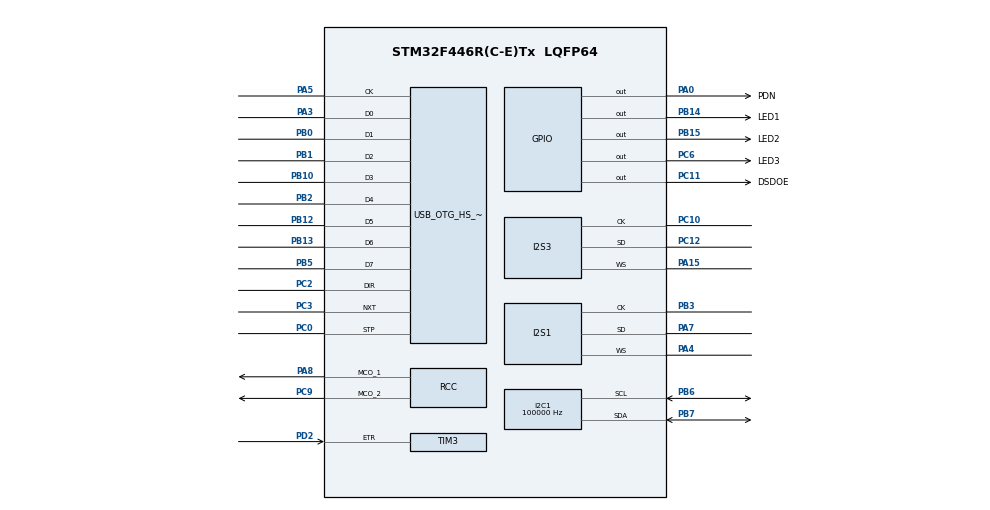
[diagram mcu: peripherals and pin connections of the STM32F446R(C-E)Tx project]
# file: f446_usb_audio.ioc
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Dma.MEMTOMEM.2.Direction=DMA_MEMORY_TO_MEMORY
Dma.MEMTOMEM.2.FIFOMode=DMA_FIFOMODE_ENABLE
Dma.MEMTOMEM.2.FIFOThreshold=DMA_FIFO_THRESHOLD_FULL
Dma.MEMTOMEM.2.Instance=DMA2_Stream0
Dma.MEMTOMEM.2.MemBurst=DMA_MBURST_SINGLE
Dma.MEMTOMEM.2.MemDataAlignment=DMA_MDATAALIGN_WORD
Dma.MEMTOMEM.2.MemInc=DMA_MINC_ENABLE
Dma.MEMTOMEM.2.Mode=DMA_NORMAL
Dma.MEMTOMEM.2.PeriphBurst=DMA_PBURST_SINGLE
Dma.MEMTOMEM.2.PeriphDataAlignment=DMA_PDATAALIGN_WORD
Dma.MEMTOMEM.2.PeriphInc=DMA_PINC_ENABLE
Dma.MEMTOMEM.2.Priority=DMA_PRIORITY_LOW
Dma.MEMTOMEM.3.Direction=DMA_MEMORY_TO_MEMORY
Dma.MEMTOMEM.3.FIFOMode=DMA_FIFOMODE_ENABLE
Dma.MEMTOMEM.3.FIFOThreshold=DMA_FIFO_THRESHOLD_FULL
Dma.MEMTOMEM.3.Instance=DMA2_Stream1
Dma.MEMTOMEM.3.MemBurst=DMA_MBURST_SINGLE
Dma.MEMTOMEM.3.MemDataAlignment=DMA_MDATAALIGN_WORD
Dma.MEMTOMEM.3.MemInc=DMA_MINC_ENABLE
Dma.MEMTOMEM.3.Mode=DMA_NORMAL
Dma.MEMTOMEM.3.PeriphBurst=DMA_PBURST_SINGLE
Dma.MEMTOMEM.3.PeriphDataAlignment=DMA_PDATAALIGN_WORD
Dma.MEMTOMEM.3.PeriphInc=DMA_PINC_DISABLE
Dma.MEMTOMEM.3.Priority=DMA_PRIORITY_LOW
Dma.Request0=SPI3_TX
Dma.Request1=SPI1_TX
Dma.Request2=MEMTOMEM
Dma.Request3=MEMTOMEM
Dma.SPI1_TX.1.Direction=DMA_MEMORY_TO_PERIPH
Dma.SPI1_TX.1.FIFOMode=DMA_FIFOMODE_ENABLE
Dma.SPI1_TX.1.FIFOThreshold=DMA_FIFO_THRESHOLD_FULL
Dma.SPI1_TX.1.Instance=DMA2_Stream3
Dma.SPI1_TX.1.MemBurst=DMA_MBURST_INC4
Dma.SPI1_TX.1.MemDataAlignment=DMA_MDATAALIGN_WORD
Dma.SPI1_TX.1.MemInc=DMA_MINC_ENABLE
Dma.SPI1_TX.1.Mode=DMA_CIRCULAR
Dma.SPI1_TX.1.PeriphBurst=DMA_PBURST_SINGLE
Dma.SPI1_TX.1.PeriphDataAlignment=DMA_PDATAALIGN_HALFWORD
Dma.SPI1_TX.1.PeriphInc=DMA_PINC_DISABLE
Dma.SPI1_TX.1.Priority=DMA_PRIORITY_LOW
Dma.SPI3_TX.0.Direction=DMA_MEMORY_TO_PERIPH
Dma.SPI3_TX.0.FIFOMode=DMA_FIFOMODE_ENABLE
Dma.SPI3_TX.0.FIFOThreshold=DMA_FIFO_THRESHOLD_FULL
Dma.SPI3_TX.0.Instance=DMA1_Stream5
Dma.SPI3_TX.0.MemBurst=DMA_MBURST_INC4
Dma.SPI3_TX.0.MemDataAlignment=DMA_MDATAALIGN_WORD
Dma.SPI3_TX.0.MemInc=DMA_MINC_ENABLE
Dma.SPI3_TX.0.Mode=DMA_CIRCULAR
Dma.SPI3_TX.0.PeriphBurst=DMA_PBURST_SINGLE
Dma.SPI3_TX.0.PeriphDataAlignment=DMA_PDATAALIGN_HALFWORD
Dma.SPI3_TX.0.PeriphInc=DMA_PINC_DISABLE
Dma.SPI3_TX.0.Priority=DMA_PRIORITY_LOW
I2C1.ClockSpeed=100000
I2C1.I2C_Mode=I2C_Standard
I2S1.AudioFreq=I2S_AUDIOFREQ_48K
I2S1.DataFormat=I2S_DATAFORMAT_32B
I2S1.ErrorAudioFreq=0.0 %
I2S1.FullDuplexMode=I2S_FULLDUPLEXMODE_DISABLE
I2S1.Instance=SPI$Index
I2S1.RealAudioFreq=48.0 KHz
I2S1.VirtualMode=I2S_MODE_SLAVE
I2S3.AudioFreq=I2S_AUDIOFREQ_48K
I2S3.CPOL=I2S_CPOL_LOW
I2S3.DataFormat=I2S_DATAFORMAT_32B
I2S3.ErrorAudioFreq=0.0 %
I2S3.FullDuplexMode=I2S_FULLDUPLEXMODE_DISABLE
I2S3.Instance=SPI$Index
I2S3.RealAudioFreq=48.0 KHz
I2S3.Standard=I2S_STANDARD_PHILIPS
I2S3.VirtualMode=I2S_MODE_MASTER
Mcu.Family=STM32F4
Mcu.Name=STM32F446R(C-E)Tx
Mcu.Package=LQFP64
NVIC.DMA1_Stream5_IRQn=true\:0\:0\:true\:false\:true\:false\:true\:true
NVIC.DMA2_Stream0_IRQn=true\:0\:0\:true\:false\:true\:true\:true\:true
NVIC.DMA2_Stream3_IRQn=true\:0\:0\:true\:false\:true\:false\:true\:true
NVIC.I2C1_EV_IRQn=true\:0\:0\:true\:false\:true\:true\:true\:true
NVIC.OTG_HS_IRQn=true\:0\:0\:true\:false\:true\:true\:true\:true
NVIC.PriorityGroup=NVIC_PRIORITYGROUP_4
NVIC.TIM3_IRQn=true\:0\:0\:true\:false\:true\:true\:true\:true
PA0-WKUP.GPIO_Label=PDN
PA0-WKUP.GPIO_Speed=GPIO_SPEED_FREQ_LOW
PA0-WKUP.PinState=GPIO_PIN_SET
PA0-WKUP.Signal=GPIO_Output
PA13.Mode=Serial_Wire
PA13.Signal=SYS_JTMS-SWDIO
PA14.Mode=Serial_Wire
PA14.Signal=SYS_JTCK-SWCLK
PA15.GPIO_PuPd=GPIO_PULLDOWN
PA15.GPIO_Speed=GPIO_SPEED_FREQ_VERY_HIGH
PA15.Mode=Half_Duplex_Master
PA15.Signal=I2S3_WS
PA3.Mode=Device_HS
PA3.Signal=USB_OTG_HS_ULPI_D0
PA4.GPIO_PuPd=GPIO_PULLDOWN
PA4.GPIO_Speed=GPIO_SPEED_FREQ_VERY_HIGH
PA4.Mode=Half_Duplex_Slave
PA4.Signal=I2S1_WS
PA5.Mode=Device_HS
PA5.Signal=USB_OTG_HS_ULPI_CK
PA7.GPIO_PuPd=GPIO_PULLDOWN
PA7.GPIO_Speed=GPIO_SPEED_FREQ_VERY_HIGH
PA7.Mode=Half_Duplex_Slave
PA7.Signal=I2S1_SD
PA8.GPIO_Speed=GPIO_SPEED_FREQ_VERY_HIGH
PA8.Mode=Clock-out-1
PA8.Signal=RCC_MCO_1
PB0.Mode=Device_HS
PB0.Signal=USB_OTG_HS_ULPI_D1
PB1.Mode=Device_HS
PB1.Signal=USB_OTG_HS_ULPI_D2
PB10.Mode=Device_HS
PB10.Signal=USB_OTG_HS_ULPI_D3
PB12.Mode=Device_HS
PB12.Signal=USB_OTG_HS_ULPI_D5
PB13.Mode=Device_HS
PB13.Signal=USB_OTG_HS_ULPI_D6
PB14.GPIO_Label=LED1
PB14.PinState=GPIO_PIN_SET
PB14.Signal=GPIO_Output
PB15.GPIO_Label=LED2
PB15.PinState=GPIO_PIN_SET
PB15.Signal=GPIO_Output
PB2.Mode=Device_HS
PB2.Signal=USB_OTG_HS_ULPI_D4
PB3.GPIO_PuPd=GPIO_PULLDOWN
PB3.GPIO_Speed=GPIO_SPEED_FREQ_VERY_HIGH
PB3.Mode=Half_Duplex_Slave
PB3.Signal=I2S1_CK
PB5.Mode=Device_HS
PB5.Signal=USB_OTG_HS_ULPI_D7
PB6.Mode=I2C
PB6.Signal=I2C1_SCL
PB7.Mode=I2C
PB7.Signal=I2C1_SDA
PC0.Mode=Device_HS
PC0.Signal=USB_OTG_HS_ULPI_STP
PC10.GPIO_PuPd=GPIO_PULLDOWN
PC10.GPIO_Speed=GPIO_SPEED_FREQ_VERY_HIGH
PC10.Mode=Half_Duplex_Master
PC10.Signal=I2S3_CK
PC11.GPIO_Label=DSDOE
PC11.GPIO_PuPd=GPIO_NOPULL
PC11.PinState=GPIO_PIN_RESET
PC11.Signal=GPIO_Output
PC12.GPIO_PuPd=GPIO_PULLDOWN
PC12.GPIO_Speed=GPIO_SPEED_FREQ_VERY_HIGH
PC12.Mode=Half_Duplex_Master
PC12.Signal=I2S3_SD
PC2.Mode=Device_HS
PC2.Signal=USB_OTG_HS_ULPI_DIR
PC3.Mode=Device_HS
PC3.Signal=USB_OTG_HS_ULPI_NXT
PC6.GPIO_Label=LED3
PC6.PinState=GPIO_PIN_SET
PC6.Signal=GPIO_Output
PC9.GPIO_Speed=GPIO_SPEED_FREQ_VERY_HIGH
PC9.Mode=Clock-out-2
PC9.Signal=RCC_MCO_2
PD2.Signal=S_TIM3_ETR
PH0-OSC_IN.Mode=HSE-External-Clock-Source
PH0-OSC_IN.Signal=RCC_OSC_IN
PH1-OSC_OUT.Mode=HSE-External-Clock-Source
PH1-OSC_OUT.Signal=RCC_OSC_OUT
ProjectManager.HeapSize=0x400
ProjectManager.StackSize=0x800
ProjectManager.TargetToolchain=STM32CubeIDE
RCC.AHBFreq_Value=192000000
RCC.APB1CLKDivider=RCC_HCLK_DIV4
RCC.APB1Freq_Value=48000000
RCC.APB1TimFreq_Value=96000000
RCC.APB2CLKDivider=RCC_HCLK_DIV2
RCC.APB2Freq_Value=96000000
RCC.APB2TimFreq_Value=192000000
RCC.CortexFreq_Value=192000000
RCC.EXTERNAL_CLOCK_VALUE=49152000
RCC.HCLKFreq_Value=192000000
RCC.HSE_Timout=100
RCC.HSE_VALUE=24576000
RCC.PLLI2SN=128
RCC.PLLN=250
RCC.PLLP=RCC_PLLP_DIV4
RCC.PLLSAIM=24
RCC.PLLSourceVirtual=RCC_PLLSOURCE_HSE
RCC.PWREXT_OverDrive=PWREXT_OverDrive_ACTIVATED
RCC.PWR_Regulator_Voltage_Scale=PWR_REGULATOR_VOLTAGE_SCALE1
RCC.RCC_MCO1Source=RCC_MCO1SOURCE_PLLCLK
RCC.RCC_MCO2Source=RCC_MCO2SOURCE_PLLI2SCLK
RCC.RCC_MCODiv1=RCC_MCODIV_4
RCC.RCC_MCODiv2=RCC_MCODIV_4
RCC.SYSCLKFreq_VALUE=192000000
RCC.SYSCLKSource=RCC_SYSCLKSOURCE_PLLRCLK
RCC.USBFreq_Value=192000000
RCC.VCOOutputFreq_Value=384000000
SH.S_TIM3_ETR.0=TIM3_ETR,TriggerSource_ETR
TIM3.Period=511
USB_OTG_HS.Sof_enable-Device_HS=DISABLE
USB_OTG_HS.VirtualMode-Device_HS=Device_HS
USB_OTG_HS.dma_enable-Device_HS=ENABLE
USB_OTG_HS.lpm_enable-Device_HS=DISABLE
USB_OTG_HS.use_dedicated_ep1-Device_HS=DISABLE
VP_TIM3_VS_ControllerModeClock.Mode=Clock Mode
board=custom

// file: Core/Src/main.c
/* USER CODE BEGIN Header */
/**
  ******************************************************************************
  * @file           : main.c
  * @brief          : Main program body
  ******************************************************************************
  * @attention
  *
  * Copyright (c) 2023 STMicroelectronics.
  * All rights reserved.
  *
  * This software is licensed under terms that can be found in the LICENSE file
  * in the root directory of this software component.
  * If no LICENSE file comes with this software, it is provided AS-IS.
  *
  ******************************************************************************
  */
/* USER CODE END Header */
#include "main.h"

/* USER CODE BEGIN Includes */
#include "usb_device.h"
#include "ak4490r.h"
/* USER CODE END Includes */

 I2C_HandleTypeDef hi2c1;

I2S_HandleTypeDef hi2s1;
I2S_HandleTypeDef hi2s3;
DMA_HandleTypeDef hdma_spi1_tx;
DMA_HandleTypeDef hdma_spi3_tx;

PCD_HandleTypeDef hpcd_USB_OTG_HS;

DMA_HandleTypeDef hdma_memtomem_dma2_stream0;
DMA_HandleTypeDef hdma_memtomem_dma2_stream1;

void SystemClock_Config(void);
void PeriphCommonClock_Config(void);
static void MX_GPIO_Init(void);
static void MX_DMA_Init(void);
static void MX_I2C1_Init(void);
static void MX_I2S1_Init(void);
static void MX_I2S3_Init(void);
static void MX_TIM3_Init(void);
static void MX_USB_OTG_HS_PCD_Init(void);

int main(void)
{

  /* MCU Configuration--------------------------------------------------------*/

  /* Reset of all peripherals, Initializes the Flash interface and the Systick. */
  HAL_Init();

  /* Configure the system clock */
  SystemClock_Config();

/* Configure the peripherals common clocks */
  PeriphCommonClock_Config();

  /* Initialize all configured peripherals */
  MX_GPIO_Init();
  MX_DMA_Init();
  MX_I2C1_Init();
  MX_I2S1_Init();
  MX_I2S3_Init();
  MX_TIM3_Init();
  MX_USB_OTG_HS_PCD_Init();
  /* USER CODE BEGIN 2 */
  MX_USB_DEVICE_Init();

  // For LRCK counting for feedback
  LL_TIM_EnableIT_UPDATE(TIM3);
  LL_TIM_EnableCounter(TIM3);
  /* USER CODE END 2 */

  /* Infinite loop */
  /* USER CODE BEGIN WHILE */
  while (1)
  {
  	AK4490R_ProcessEvents();
    /* USER CODE END WHILE */

  }
}

void SystemClock_Config(void)
{
  LL_FLASH_SetLatency(LL_FLASH_LATENCY_5);
  while(LL_FLASH_GetLatency()!= LL_FLASH_LATENCY_5)
  {
  }
  LL_PWR_SetRegulVoltageScaling(LL_PWR_REGU_VOLTAGE_SCALE1);
  LL_PWR_EnableOverDriveMode();
  LL_RCC_HSE_EnableBypass();
  LL_RCC_HSE_Enable();

   /* Wait till HSE is ready */
  while(LL_RCC_HSE_IsReady() != 1)
  {

  }
  LL_RCC_PLL_ConfigDomain_SYS(LL_RCC_PLLSOURCE_HSE, LL_RCC_PLLM_DIV_16, 250, LL_RCC_PLLP_DIV_4);
  LL_RCC_PLL_ConfigDomain_SYS(LL_RCC_PLLSOURCE_HSE, LL_RCC_PLLM_DIV_16, 250, LL_RCC_PLLR_DIV_2);
  RCC->PLLCFGR |= 1 << 16;
  LL_RCC_PLL_Enable();

   /* Wait till PLL is ready */
  while(LL_RCC_PLL_IsReady() != 1)
  {

  }
  LL_RCC_SetAHBPrescaler(LL_RCC_SYSCLK_DIV_1);
  LL_RCC_SetAPB1Prescaler(LL_RCC_APB1_DIV_4);
  LL_RCC_SetAPB2Prescaler(LL_RCC_APB2_DIV_2);
  LL_RCC_SetSysClkSource(LL_RCC_SYS_CLKSOURCE_PLLR);

   /* Wait till System clock is ready */
  while(LL_RCC_GetSysClkSource() != LL_RCC_SYS_CLKSOURCE_STATUS_PLLR)
  {

  }
  LL_SetSystemCoreClock(192000000);

   /* Update the time base */
  if (HAL_InitTick (TICK_INT_PRIORITY) != HAL_OK)
  {
    Error_Handler();
  }
  LL_RCC_ConfigMCO(LL_RCC_MCO1SOURCE_PLLCLK, LL_RCC_MCO1_DIV_4);
  LL_RCC_ConfigMCO(LL_RCC_MCO2SOURCE_PLLI2S, LL_RCC_MCO2_DIV_4);
  LL_RCC_SetTIMPrescaler(LL_RCC_TIM_PRESCALER_TWICE);
}

void PeriphCommonClock_Config(void)
{
  LL_RCC_PLLI2S_ConfigDomain_I2S(LL_RCC_PLLSOURCE_HSE, LL_RCC_PLLI2SM_DIV_16, 128, LL_RCC_PLLI2SR_DIV_2);
  LL_RCC_PLLI2S_Enable();

   /* Wait till PLL is ready */
  while(LL_RCC_PLLI2S_IsReady() != 1)
  {

  }
}

static void MX_I2C1_Init(void)
{

  hi2c1.Instance = I2C1;
  hi2c1.Init.ClockSpeed = 100000;
  hi2c1.Init.DutyCycle = I2C_DUTYCYCLE_2;
  hi2c1.Init.OwnAddress1 = 0;
  hi2c1.Init.AddressingMode = I2C_ADDRESSINGMODE_7BIT;
  hi2c1.Init.DualAddressMode = I2C_DUALADDRESS_DISABLE;
  hi2c1.Init.OwnAddress2 = 0;
  hi2c1.Init.GeneralCallMode = I2C_GENERALCALL_DISABLE;
  hi2c1.Init.NoStretchMode = I2C_NOSTRETCH_DISABLE;
  if (HAL_I2C_Init(&hi2c1) != HAL_OK)
  {
    Error_Handler();
  }

}

static void MX_I2S1_Init(void)
{

  hi2s1.Instance = SPI1;
  hi2s1.Init.Mode = I2S_MODE_SLAVE_TX;
  hi2s1.Init.Standard = I2S_STANDARD_PHILIPS;
  hi2s1.Init.DataFormat = I2S_DATAFORMAT_32B;
  hi2s1.Init.MCLKOutput = I2S_MCLKOUTPUT_DISABLE;
  hi2s1.Init.AudioFreq = I2S_AUDIOFREQ_48K;
  hi2s1.Init.CPOL = I2S_CPOL_LOW;
  hi2s1.Init.ClockSource = I2S_CLOCK_PLL;
  hi2s1.Init.FullDuplexMode = I2S_FULLDUPLEXMODE_DISABLE;
  if (HAL_I2S_Init(&hi2s1) != HAL_OK)
  {
    Error_Handler();
  }

}

static void MX_I2S3_Init(void)
{

  hi2s3.Instance = SPI3;
  hi2s3.Init.Mode = I2S_MODE_MASTER_TX;
  hi2s3.Init.Standard = I2S_STANDARD_PHILIPS;
  hi2s3.Init.DataFormat = I2S_DATAFORMAT_32B;
  hi2s3.Init.MCLKOutput = I2S_MCLKOUTPUT_DISABLE;
  hi2s3.Init.AudioFreq = I2S_AUDIOFREQ_48K;
  hi2s3.Init.CPOL = I2S_CPOL_LOW;
  hi2s3.Init.ClockSource = I2S_CLOCK_PLL;
  hi2s3.Init.FullDuplexMode = I2S_FULLDUPLEXMODE_DISABLE;
  if (HAL_I2S_Init(&hi2s3) != HAL_OK)
  {
    Error_Handler();
  }

}

static void MX_TIM3_Init(void)
{

  LL_TIM_InitTypeDef TIM_InitStruct = {0};

  LL_GPIO_InitTypeDef GPIO_InitStruct = {0};

  /* Peripheral clock enable */
  LL_APB1_GRP1_EnableClock(LL_APB1_GRP1_PERIPH_TIM3);

  LL_AHB1_GRP1_EnableClock(LL_AHB1_GRP1_PERIPH_GPIOD);
  /**TIM3 GPIO Configuration
  PD2   ------> TIM3_ETR
  */
  GPIO_InitStruct.Pin = LL_GPIO_PIN_2;
  GPIO_InitStruct.Mode = LL_GPIO_MODE_ALTERNATE;
  GPIO_InitStruct.Speed = LL_GPIO_SPEED_FREQ_LOW;
  GPIO_InitStruct.OutputType = LL_GPIO_OUTPUT_PUSHPULL;
  GPIO_InitStruct.Pull = LL_GPIO_PULL_NO;
  GPIO_InitStruct.Alternate = LL_GPIO_AF_2;
  LL_GPIO_Init(GPIOD, &GPIO_InitStruct);

  /* TIM3 interrupt Init */
  NVIC_SetPriority(TIM3_IRQn, NVIC_EncodePriority(NVIC_GetPriorityGrouping(),0, 0));
  NVIC_EnableIRQ(TIM3_IRQn);

  TIM_InitStruct.Prescaler = 0;
  TIM_InitStruct.CounterMode = LL_TIM_COUNTERMODE_UP;
  TIM_InitStruct.Autoreload = 511;
  TIM_InitStruct.ClockDivision = LL_TIM_CLOCKDIVISION_DIV1;
  LL_TIM_Init(TIM3, &TIM_InitStruct);
  LL_TIM_DisableARRPreload(TIM3);
  LL_TIM_SetTriggerInput(TIM3, LL_TIM_TS_ETRF);
  LL_TIM_SetClockSource(TIM3, LL_TIM_CLOCKSOURCE_EXT_MODE1);
  LL_TIM_DisableExternalClock(TIM3);
  LL_TIM_ConfigETR(TIM3, LL_TIM_ETR_POLARITY_NONINVERTED, LL_TIM_ETR_PRESCALER_DIV1, LL_TIM_ETR_FILTER_FDIV1);
  LL_TIM_DisableIT_TRIG(TIM3);
  LL_TIM_DisableDMAReq_TRIG(TIM3);
  LL_TIM_SetTriggerOutput(TIM3, LL_TIM_TRGO_RESET);
  LL_TIM_DisableMasterSlaveMode(TIM3);

}

static void MX_USB_OTG_HS_PCD_Init(void)
{

  hpcd_USB_OTG_HS.Instance = USB_OTG_HS;
  hpcd_USB_OTG_HS.Init.dev_endpoints = 8;
  hpcd_USB_OTG_HS.Init.speed = PCD_SPEED_HIGH;
  hpcd_USB_OTG_HS.Init.dma_enable = ENABLE;
  hpcd_USB_OTG_HS.Init.phy_itface = USB_OTG_ULPI_PHY;
  hpcd_USB_OTG_HS.Init.Sof_enable = DISABLE;
  hpcd_USB_OTG_HS.Init.low_power_enable = DISABLE;
  hpcd_USB_OTG_HS.Init.lpm_enable = DISABLE;
  hpcd_USB_OTG_HS.Init.vbus_sensing_enable = DISABLE;
  hpcd_USB_OTG_HS.Init.use_dedicated_ep1 = DISABLE;
  hpcd_USB_OTG_HS.Init.use_external_vbus = DISABLE;
  if (HAL_PCD_Init(&hpcd_USB_OTG_HS) != HAL_OK)
  {
    Error_Handler();
  }
  /* USER CODE BEGIN USB_OTG_HS_Init 2 */
  HAL_PCDEx_SetRxFiFo(&hpcd_USB_OTG_HS, 0x200);
  HAL_PCDEx_SetTxFiFo(&hpcd_USB_OTG_HS, 0, 0x80);
  HAL_PCDEx_SetTxFiFo(&hpcd_USB_OTG_HS, 1, 0x174);
  /* USER CODE END USB_OTG_HS_Init 2 */

}

static void MX_DMA_Init(void)
{

  /* DMA controller clock enable */
  __HAL_RCC_DMA1_CLK_ENABLE();
  __HAL_RCC_DMA2_CLK_ENABLE();

  /* Configure DMA request hdma_memtomem_dma2_stream0 on DMA2_Stream0 */
  hdma_memtomem_dma2_stream0.Instance = DMA2_Stream0;
  hdma_memtomem_dma2_stream0.Init.Channel = DMA_CHANNEL_0;
  hdma_memtomem_dma2_stream0.Init.Direction = DMA_MEMORY_TO_MEMORY;
  hdma_memtomem_dma2_stream0.Init.PeriphInc = DMA_PINC_ENABLE;
  hdma_memtomem_dma2_stream0.Init.MemInc = DMA_MINC_ENABLE;
  hdma_memtomem_dma2_stream0.Init.PeriphDataAlignment = DMA_PDATAALIGN_WORD;
  hdma_memtomem_dma2_stream0.Init.MemDataAlignment = DMA_MDATAALIGN_WORD;
  hdma_memtomem_dma2_stream0.Init.Mode = DMA_NORMAL;
  hdma_memtomem_dma2_stream0.Init.Priority = DMA_PRIORITY_LOW;
  hdma_memtomem_dma2_stream0.Init.FIFOMode = DMA_FIFOMODE_ENABLE;
  hdma_memtomem_dma2_stream0.Init.FIFOThreshold = DMA_FIFO_THRESHOLD_FULL;
  hdma_memtomem_dma2_stream0.Init.MemBurst = DMA_MBURST_SINGLE;
  hdma_memtomem_dma2_stream0.Init.PeriphBurst = DMA_PBURST_SINGLE;
  if (HAL_DMA_Init(&hdma_memtomem_dma2_stream0) != HAL_OK)
  {
    Error_Handler( );
  }

  /* Configure DMA request hdma_memtomem_dma2_stream1 on DMA2_Stream1 */
  hdma_memtomem_dma2_stream1.Instance = DMA2_Stream1;
  hdma_memtomem_dma2_stream1.Init.Channel = DMA_CHANNEL_0;
  hdma_memtomem_dma2_stream1.Init.Direction = DMA_MEMORY_TO_MEMORY;
  hdma_memtomem_dma2_stream1.Init.PeriphInc = DMA_PINC_DISABLE;
  hdma_memtomem_dma2_stream1.Init.MemInc = DMA_MINC_ENABLE;
  hdma_memtomem_dma2_stream1.Init.PeriphDataAlignment = DMA_PDATAALIGN_WORD;
  hdma_memtomem_dma2_stream1.Init.MemDataAlignment = DMA_MDATAALIGN_WORD;
  hdma_memtomem_dma2_stream1.Init.Mode = DMA_NORMAL;
  hdma_memtomem_dma2_stream1.Init.Priority = DMA_PRIORITY_LOW;
  hdma_memtomem_dma2_stream1.Init.FIFOMode = DMA_FIFOMODE_ENABLE;
  hdma_memtomem_dma2_stream1.Init.FIFOThreshold = DMA_FIFO_THRESHOLD_FULL;
  hdma_memtomem_dma2_stream1.Init.MemBurst = DMA_MBURST_SINGLE;
  hdma_memtomem_dma2_stream1.Init.PeriphBurst = DMA_PBURST_SINGLE;
  if (HAL_DMA_Init(&hdma_memtomem_dma2_stream1) != HAL_OK)
  {
    Error_Handler( );
  }

  /* DMA interrupt init */
  /* DMA1_Stream5_IRQn interrupt configuration */
  HAL_NVIC_SetPriority(DMA1_Stream5_IRQn, 0, 0);
  HAL_NVIC_EnableIRQ(DMA1_Stream5_IRQn);
  /* DMA2_Stream0_IRQn interrupt configuration */
  HAL_NVIC_SetPriority(DMA2_Stream0_IRQn, 0, 0);
  HAL_NVIC_EnableIRQ(DMA2_Stream0_IRQn);
  /* DMA2_Stream3_IRQn interrupt configuration */
  HAL_NVIC_SetPriority(DMA2_Stream3_IRQn, 0, 0);
  HAL_NVIC_EnableIRQ(DMA2_Stream3_IRQn);

}

static void MX_GPIO_Init(void)
{
  LL_GPIO_InitTypeDef GPIO_InitStruct = {0};

  /* GPIO Ports Clock Enable */
  LL_AHB1_GRP1_EnableClock(LL_AHB1_GRP1_PERIPH_GPIOH);
  LL_AHB1_GRP1_EnableClock(LL_AHB1_GRP1_PERIPH_GPIOC);
  LL_AHB1_GRP1_EnableClock(LL_AHB1_GRP1_PERIPH_GPIOA);
  LL_AHB1_GRP1_EnableClock(LL_AHB1_GRP1_PERIPH_GPIOB);
  LL_AHB1_GRP1_EnableClock(LL_AHB1_GRP1_PERIPH_GPIOD);

  /**/
  LL_GPIO_SetOutputPin(PDN_GPIO_Port, PDN_Pin);

  /**/
  LL_GPIO_SetOutputPin(GPIOB, LED1_Pin|LED2_Pin);

  /**/
  LL_GPIO_SetOutputPin(LED3_GPIO_Port, LED3_Pin);

  /**/
  LL_GPIO_ResetOutputPin(DSDOE_GPIO_Port, DSDOE_Pin);

  /**/
  GPIO_InitStruct.Pin = PDN_Pin;
  GPIO_InitStruct.Mode = LL_GPIO_MODE_OUTPUT;
  GPIO_InitStruct.Speed = LL_GPIO_SPEED_FREQ_LOW;
  GPIO_InitStruct.OutputType = LL_GPIO_OUTPUT_PUSHPULL;
  GPIO_InitStruct.Pull = LL_GPIO_PULL_NO;
  LL_GPIO_Init(PDN_GPIO_Port, &GPIO_InitStruct);

  /**/
  GPIO_InitStruct.Pin = LED1_Pin|LED2_Pin;
  GPIO_InitStruct.Mode = LL_GPIO_MODE_OUTPUT;
  GPIO_InitStruct.Speed = LL_GPIO_SPEED_FREQ_LOW;
  GPIO_InitStruct.OutputType = LL_GPIO_OUTPUT_PUSHPULL;
  GPIO_InitStruct.Pull = LL_GPIO_PULL_NO;
  LL_GPIO_Init(GPIOB, &GPIO_InitStruct);

  /**/
  GPIO_InitStruct.Pin = LED3_Pin|DSDOE_Pin;
  GPIO_InitStruct.Mode = LL_GPIO_MODE_OUTPUT;
  GPIO_InitStruct.Speed = LL_GPIO_SPEED_FREQ_LOW;
  GPIO_InitStruct.OutputType = LL_GPIO_OUTPUT_PUSHPULL;
  GPIO_InitStruct.Pull = LL_GPIO_PULL_NO;
  LL_GPIO_Init(GPIOC, &GPIO_InitStruct);

  /**/
  GPIO_InitStruct.Pin = LL_GPIO_PIN_9;
  GPIO_InitStruct.Mode = LL_GPIO_MODE_ALTERNATE;
  GPIO_InitStruct.Speed = LL_GPIO_SPEED_FREQ_VERY_HIGH;
  GPIO_InitStruct.OutputType = LL_GPIO_OUTPUT_PUSHPULL;
  GPIO_InitStruct.Pull = LL_GPIO_PULL_NO;
  GPIO_InitStruct.Alternate = LL_GPIO_AF_0;
  LL_GPIO_Init(GPIOC, &GPIO_InitStruct);

  /**/
  GPIO_InitStruct.Pin = LL_GPIO_PIN_8;
  GPIO_InitStruct.Mode = LL_GPIO_MODE_ALTERNATE;
  GPIO_InitStruct.Speed = LL_GPIO_SPEED_FREQ_VERY_HIGH;
  GPIO_InitStruct.OutputType = LL_GPIO_OUTPUT_PUSHPULL;
  GPIO_InitStruct.Pull = LL_GPIO_PULL_NO;
  GPIO_InitStruct.Alternate = LL_GPIO_AF_0;
  LL_GPIO_Init(GPIOA, &GPIO_InitStruct);

}

void Error_Handler(void)
{
  /* USER CODE BEGIN Error_Handler_Debug */
  /* User can add his own implementation to report the HAL error return state */
  __disable_irq();
  NVIC_SystemReset();
  while (1)
  {
  }
  /* USER CODE END Error_Handler_Debug */
}
